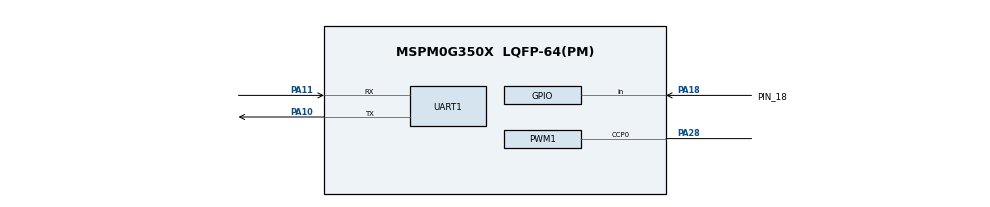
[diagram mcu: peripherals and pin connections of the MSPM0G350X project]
/**
 * @cliArgs --device "MSPM0G350X" --package "LQFP-64(PM)" --part "Default" --product "mspm0_sdk@2.01.00.03"
 * @versions {"tool":"1.20.0+3587"}
 */

/**
 * Import the modules used in this configuration.
 */
const GPIO    = scripting.addModule("/ti/driverlib/GPIO", {}, false);
const GPIO1   = GPIO.addInstance();
const GPIO2   = GPIO.addInstance();
const GPIO3   = GPIO.addInstance();
const PWM     = scripting.addModule("/ti/driverlib/PWM", {}, false);
const PWM1    = PWM.addInstance();
const PWM2    = PWM.addInstance();
const PWM3    = PWM.addInstance();
const SYSCTL  = scripting.addModule("/ti/driverlib/SYSCTL");
const SYSTICK = scripting.addModule("/ti/driverlib/SYSTICK");
const UART    = scripting.addModule("/ti/driverlib/UART", {}, false);
const UART1   = UART.addInstance();

/**
 * Write custom configuration values to the imported modules.
 */
const gate7  = system.clockTree["MFCLKGATE"];
gate7.enable = true;

GPIO1.$name                              = "KEY";
GPIO1.port                               = "PORTA";
GPIO1.associatedPins[0].$name            = "PIN_18";
GPIO1.associatedPins[0].direction        = "INPUT";
GPIO1.associatedPins[0].assignedPin      = "18";
GPIO1.associatedPins[0].internalResistor = "PULL_DOWN";
GPIO1.associatedPins[0].interruptEn      = true;
GPIO1.associatedPins[0].polarity         = "RISE";
GPIO1.associatedPins[0].pin.$assign      = "PA18";

const Board = scripting.addModule("/ti/driverlib/Board", {}, false);

GPIO2.port                          = "PORTA";
GPIO2.$name                         = "AIN";
GPIO2.associatedPins.create(2);
GPIO2.associatedPins[0].$name       = "AIN1";
GPIO2.associatedPins[0].assignedPin = "12";
GPIO2.associatedPins[1].$name       = "AIN2";
GPIO2.associatedPins[1].assignedPin = "13";

GPIO3.$name                         = "BIN";
GPIO3.port                          = "PORTA";
GPIO3.associatedPins.create(2);
GPIO3.associatedPins[0].$name       = "BIN1";
GPIO3.associatedPins[0].assignedPin = "15";
GPIO3.associatedPins[1].$name       = "BIN2";
GPIO3.associatedPins[1].assignedPin = "16";

PWM1.ccIndex                            = [0];
PWM1.timerCount                         = 20000;
PWM1.timerStartTimer                    = true;
PWM1.clockPrescale                      = 32;
PWM1.pwmMode                            = "EDGE_ALIGN_UP";
PWM1.$name                              = "PWM_SERVO";
PWM1.peripheral.ccp0Pin.$assign         = "PA28";
PWM1.PWM_CHANNEL_0.$name                = "ti_driverlib_pwm_PWMTimerCC1";
PWM1.ccp0PinConfig.direction            = scripting.forceWrite("OUTPUT");
PWM1.ccp0PinConfig.hideOutputInversion  = scripting.forceWrite(false);
PWM1.ccp0PinConfig.onlyInternalResistor = scripting.forceWrite(false);
PWM1.ccp0PinConfig.passedPeripheralType = scripting.forceWrite("Digital");
PWM1.ccp0PinConfig.$name                = "ti_driverlib_gpio_GPIOPinGeneric3";

PWM2.$name                 = "PWM_MOTOR_A";
PWM2.ccIndex               = [0];
PWM2.clockDivider          = 2;
PWM2.timerStartTimer       = true;
PWM2.pwmMode               = "EDGE_ALIGN_UP";
PWM2.peripheral.$assign    = "TIMG12";
PWM2.PWM_CHANNEL_0.$name   = "ti_driverlib_pwm_PWMTimerCC0";
PWM2.PWM_CHANNEL_0.ccValue = 4000;
PWM2.ccp0PinConfig.$name   = "ti_driverlib_gpio_GPIOPinGeneric2";

PWM3.$name                 = "PWM_MOTOR_B";
PWM3.ccIndex               = [0];
PWM3.clockDivider          = 2;
PWM3.timerStartTimer       = true;
PWM3.pwmMode               = "EDGE_ALIGN_UP";
PWM3.peripheral.$assign    = "TIMG7";
PWM3.PWM_CHANNEL_0.$name   = "ti_driverlib_pwm_PWMTimerCC2";
PWM3.PWM_CHANNEL_0.ccValue = 4000;
PWM3.ccp0PinConfig.$name   = "ti_driverlib_gpio_GPIOPinGeneric4";

SYSCTL.forceDefaultClkConfig = true;
SYSCTL.clockTreeEn           = true;

SYSTICK.periodEnable      = true;
SYSTICK.period            = 32000;
SYSTICK.systickEnable     = true;
SYSTICK.interruptPriority = "0";

UART1.$name                    = "UART_0";
UART1.uartClkSrc               = "MFCLK";
UART1.enabledInterrupts        = ["RX"];
UART1.peripheral.$assign       = "UART0";
UART1.peripheral.rxPin.$assign = "PA11";
UART1.peripheral.txPin.$assign = "PA10";
UART1.txPinConfig.$name        = "ti_driverlib_gpio_GPIOPinGeneric0";
UART1.rxPinConfig.$name        = "ti_driverlib_gpio_GPIOPinGeneric1";

/**
 * Pinmux solution for unlocked pins/peripherals. This ensures that minor changes to the automatic solver in a future
 * version of the tool will not impact the pinmux you originally saw.  These lines can be completely deleted in order to
 * re-solve from scratch.
 */
Board.peripheral.$suggestSolution            = "DEBUGSS";
Board.peripheral.swclkPin.$suggestSolution   = "PA20";
Board.peripheral.swdioPin.$suggestSolution   = "PA19";
GPIO2.associatedPins[0].pin.$suggestSolution = "PA12";
GPIO2.associatedPins[1].pin.$suggestSolution = "PA13";
GPIO3.associatedPins[0].pin.$suggestSolution = "PA15";
GPIO3.associatedPins[1].pin.$suggestSolution = "PA16";
PWM1.peripheral.$suggestSolution             = "TIMA1";
PWM2.peripheral.ccp0Pin.$suggestSolution     = "PA14";
PWM3.peripheral.ccp0Pin.$suggestSolution     = "PA17";
